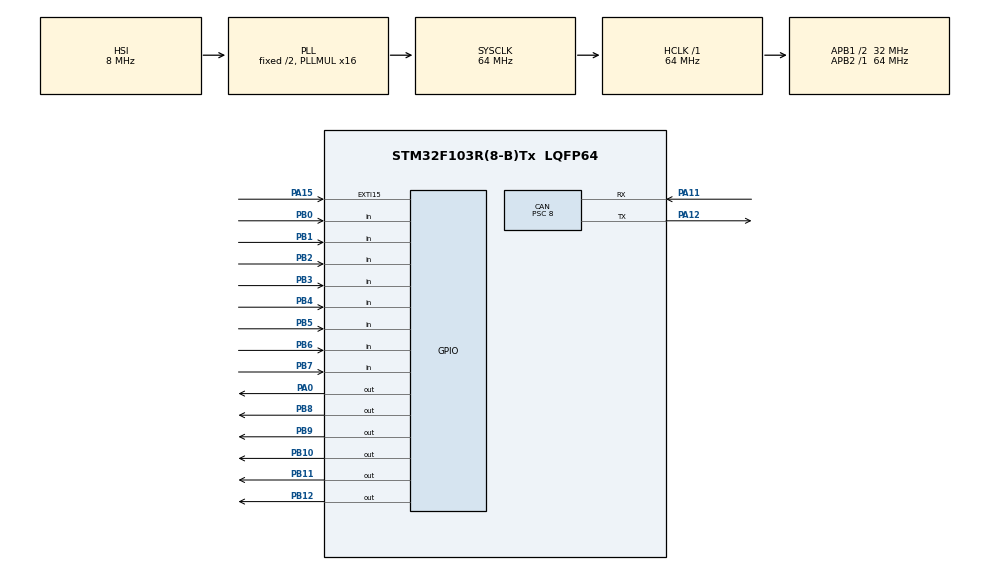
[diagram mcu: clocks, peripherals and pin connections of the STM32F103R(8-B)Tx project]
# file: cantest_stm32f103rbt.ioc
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Mcu.Family=STM32F1
PA11.Mode=Master
RCC.APB1CLKDivider=RCC_HCLK_DIV2
PB11.Signal=GPIO_Output
CAN.CalculateTimeBit=2000
RCC.SYSCLKSource=RCC_SYSCLKSOURCE_PLLCLK
ProjectManager.StackSize=0x400
PA0-WKUP.Signal=GPIO_Output
PA13.Signal=SYS_JTMS-SWDIO
PA12.Signal=CAN_TX
CAN.BS2=CAN_BS2_4TQ
NVIC.USB_HP_CAN1_TX_IRQn=true\:0\:0\:false\:false\:true\:true\:true
CAN.Prescaler=8
CAN.BS1=CAN_BS1_3TQ
ProjectManager.TargetToolchain=Makefile
PA15.GPIO_ModeDefaultEXTI=GPIO_MODE_IT_FALLING
RCC.HCLKFreq_Value=64000000
RCC.APB2TimFreq_Value=64000000
PB6.Signal=GPIO_Input
RCC.USBFreq_Value=64000000
CAN.Mode=CAN_MODE_SILENT
RCC.AHBFreq_Value=64000000
PB10.Signal=GPIO_Output
NVIC.EXTI15_10_IRQn=true\:0\:0\:false\:false\:true\:true\:true
PB2.Signal=GPIO_Input
board=custom
RCC.PLLMUL=RCC_PLL_MUL16
RCC.APB2Freq_Value=64000000
PA14.Mode=Serial_Wire
NVIC.USB_LP_CAN1_RX0_IRQn=true\:0\:0\:false\:false\:true\:true\:true
PB7.Signal=GPIO_Input
PA13.Mode=Serial_Wire
Mcu.Name=STM32F103R(8-B)Tx
CAN.CalculateTimeQuantum=250.0
PB3.Signal=GPIO_Input
RCC.SYSCLKFreq_VALUE=64000000
Mcu.Package=LQFP64
PB5.Signal=GPIO_Input
PB9.Signal=GPIO_Output
PB1.Signal=GPIO_Input
PA12.Mode=Master
PA11.Signal=CAN_RX
PA14.Signal=SYS_JTCK-SWCLK
PA15.Signal=GPXTI15
ProjectManager.HeapSize=0x200
NVIC.PriorityGroup=NVIC_PRIORITYGROUP_4
RCC.APB1TimFreq_Value=64000000
PB8.Signal=GPIO_Output
RCC.APB1Freq_Value=32000000
PB0.Signal=GPIO_Input
PB12.Signal=GPIO_Output
PB4.Signal=GPIO_Input

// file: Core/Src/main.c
/* USER CODE BEGIN Header */
/**
  ******************************************************************************
  * @file           : main.c
  * @brief          : Main program body
  ******************************************************************************
  * @attention
  *
  * <h2><center>&copy; Copyright (c) 2021 STMicroelectronics.
  * All rights reserved.</center></h2>
  *
  * This software component is licensed by ST under BSD 3-Clause license,
  * the "License"; You may not use this file except in compliance with the
  * License. You may obtain a copy of the License at:
  *                        opensource.org/licenses/BSD-3-Clause
  *
  ******************************************************************************
  */
/* USER CODE END Header */
#include "main.h"

/* USER CODE BEGIN Includes */
#include "my.h"
/* USER CODE END Includes */

CAN_HandleTypeDef hcan;

void SystemClock_Config(void);
static void MX_GPIO_Init(void);
static void MX_CAN_Init(void);

int main(void)
{

  /* MCU Configuration--------------------------------------------------------*/

  /* Reset of all peripherals, Initializes the Flash interface and the Systick. */
  HAL_Init();

  /* Configure the system clock */
  SystemClock_Config();

  /* Initialize all configured peripherals */
  MX_GPIO_Init();
  MX_CAN_Init();

  /* Infinite loop */
  while (1)
  {

    /* USER CODE BEGIN 3 */
      MyMain();
  }
  /* USER CODE END 3 */
}

void SystemClock_Config(void)
{
  RCC_OscInitTypeDef RCC_OscInitStruct = {0};
  RCC_ClkInitTypeDef RCC_ClkInitStruct = {0};

  /** Initializes the RCC Oscillators according to the specified parameters
  * in the RCC_OscInitTypeDef structure.
  */
  RCC_OscInitStruct.OscillatorType = RCC_OSCILLATORTYPE_HSI;
  RCC_OscInitStruct.HSIState = RCC_HSI_ON;
  RCC_OscInitStruct.HSICalibrationValue = RCC_HSICALIBRATION_DEFAULT;
  RCC_OscInitStruct.PLL.PLLState = RCC_PLL_ON;
  RCC_OscInitStruct.PLL.PLLSource = RCC_PLLSOURCE_HSI_DIV2;
  RCC_OscInitStruct.PLL.PLLMUL = RCC_PLL_MUL16;
  if (HAL_RCC_OscConfig(&RCC_OscInitStruct) != HAL_OK)
  {
    Error_Handler();
  }
  /** Initializes the CPU, AHB and APB buses clocks
  */
  RCC_ClkInitStruct.ClockType = RCC_CLOCKTYPE_HCLK|RCC_CLOCKTYPE_SYSCLK
                              |RCC_CLOCKTYPE_PCLK1|RCC_CLOCKTYPE_PCLK2;
  RCC_ClkInitStruct.SYSCLKSource = RCC_SYSCLKSOURCE_PLLCLK;
  RCC_ClkInitStruct.AHBCLKDivider = RCC_SYSCLK_DIV1;
  RCC_ClkInitStruct.APB1CLKDivider = RCC_HCLK_DIV2;
  RCC_ClkInitStruct.APB2CLKDivider = RCC_HCLK_DIV1;

  if (HAL_RCC_ClockConfig(&RCC_ClkInitStruct, FLASH_LATENCY_2) != HAL_OK)
  {
    Error_Handler();
  }
}

static void MX_CAN_Init(void)
{

  hcan.Instance = CAN1;
  hcan.Init.Prescaler = 8;
  hcan.Init.Mode = CAN_MODE_SILENT;
  hcan.Init.SyncJumpWidth = CAN_SJW_1TQ;
  hcan.Init.TimeSeg1 = CAN_BS1_3TQ;
  hcan.Init.TimeSeg2 = CAN_BS2_4TQ;
  hcan.Init.TimeTriggeredMode = DISABLE;
  hcan.Init.AutoBusOff = DISABLE;
  hcan.Init.AutoWakeUp = DISABLE;
  hcan.Init.AutoRetransmission = DISABLE;
  hcan.Init.ReceiveFifoLocked = DISABLE;
  hcan.Init.TransmitFifoPriority = DISABLE;
  if (HAL_CAN_Init(&hcan) != HAL_OK)
  {
    Error_Handler();
  }

}

static void MX_GPIO_Init(void)
{
  GPIO_InitTypeDef GPIO_InitStruct = {0};

  /* GPIO Ports Clock Enable */
  __HAL_RCC_GPIOA_CLK_ENABLE();
  __HAL_RCC_GPIOB_CLK_ENABLE();

  /*Configure GPIO pin Output Level */
  HAL_GPIO_WritePin(GPIOA, GPIO_PIN_0, GPIO_PIN_RESET);

  /*Configure GPIO pin Output Level */
  HAL_GPIO_WritePin(GPIOB, GPIO_PIN_10|GPIO_PIN_11|GPIO_PIN_12|GPIO_PIN_8
                          |GPIO_PIN_9, GPIO_PIN_RESET);

  /*Configure GPIO pin : PA0 */
  GPIO_InitStruct.Pin = GPIO_PIN_0;
  GPIO_InitStruct.Mode = GPIO_MODE_OUTPUT_PP;
  GPIO_InitStruct.Pull = GPIO_NOPULL;
  GPIO_InitStruct.Speed = GPIO_SPEED_FREQ_LOW;
  HAL_GPIO_Init(GPIOA, &GPIO_InitStruct);

  /*Configure GPIO pins : PB0 PB1 PB2 PB3
                           PB4 PB5 PB6 PB7 */
  GPIO_InitStruct.Pin = GPIO_PIN_0|GPIO_PIN_1|GPIO_PIN_2|GPIO_PIN_3
                          |GPIO_PIN_4|GPIO_PIN_5|GPIO_PIN_6|GPIO_PIN_7;
  GPIO_InitStruct.Mode = GPIO_MODE_INPUT;
  GPIO_InitStruct.Pull = GPIO_NOPULL;
  HAL_GPIO_Init(GPIOB, &GPIO_InitStruct);

  /*Configure GPIO pins : PB10 PB11 PB12 PB8
                           PB9 */
  GPIO_InitStruct.Pin = GPIO_PIN_10|GPIO_PIN_11|GPIO_PIN_12|GPIO_PIN_8
                          |GPIO_PIN_9;
  GPIO_InitStruct.Mode = GPIO_MODE_OUTPUT_PP;
  GPIO_InitStruct.Pull = GPIO_NOPULL;
  GPIO_InitStruct.Speed = GPIO_SPEED_FREQ_LOW;
  HAL_GPIO_Init(GPIOB, &GPIO_InitStruct);

  /*Configure GPIO pin : PA15 */
  GPIO_InitStruct.Pin = GPIO_PIN_15;
  GPIO_InitStruct.Mode = GPIO_MODE_IT_FALLING;
  GPIO_InitStruct.Pull = GPIO_NOPULL;
  HAL_GPIO_Init(GPIOA, &GPIO_InitStruct);

  /* EXTI interrupt init*/
  HAL_NVIC_SetPriority(EXTI15_10_IRQn, 0, 0);
  HAL_NVIC_EnableIRQ(EXTI15_10_IRQn);

}

void Error_Handler(void)
{
    for(;;) {
    }
}

/************************ (C) COPYRIGHT STMicroelectronics *****END OF FILE****/
